# R7FA4C1BD register map
Vendor: Renesas Electronics Corporation; Series: RA4; File version: 1.10.00
CPU: CM33 r0p4, little endian, MPU, FPU, VTOR, 4 interrupt priority bits, 96 interrupts
Registers are 32-bit, read-write, reset 0x0 unless marked. A register's access mark holds for its fields unless they carry their own. Offsets are from the block's base; [hi:lo] are bit positions; {n}, {i} and the like mark numbered series; 'fields as' and 'values as' point back to an identical list.

## PFS — Control Register
Base 0x4001F800
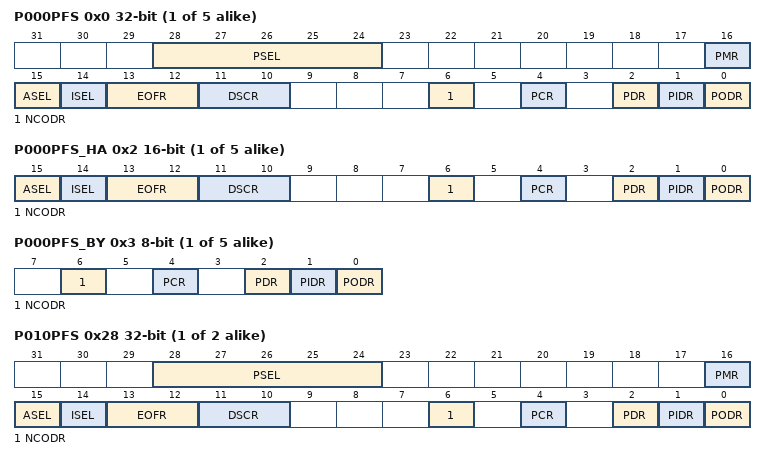
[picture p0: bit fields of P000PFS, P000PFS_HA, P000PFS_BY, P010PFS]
{0x0+4i} P00{i}PFS (i=0..4) (reset mask 0xFFFFFFFD) — Port 00{i} Pin Function Select Register
  [28:24] PSEL — Peripheral Select
  [16] PMR — Port Mode Control
    0=Use as general I/O pin; 1=Use as I/O port for peripheral functions
  [15] ASEL — Analog Input Enable
    0=Do not use as analog pin; 1=Use as analog pin
  [14] ISEL — IRQ Input Enable
    0=Do not use as IRQn input pin; 1=Use as IRQn input pin
  [13:12] EOFR — Event on Falling/Event on Rising
    0=Don't care; 1=Detect rising edge; 2=Detect falling edge; 3=Detect both edges
  [11:10] DSCR — Port Drive Capability
    0=Low drive; 1=Middle drive; 2=Setting prohibited; 3=High drive
  [6] NCODR — N-Channel Open-Drain Control
    0=Output CMOS; 1=Output NMOS open-drain
  [4] PCR — Pull-up Control
    0=Disable input pull-up; 1=Enable input pull-up
  [2] PDR — Port Direction
    0=Input (functions as an input pin); 1=Output (functions as an output pin)
  [1] PIDR ro — Port State
    0=Low level; 1=High level
  [0] PODR — Port Output Data
    0=Output low; 1=Output high
{0x2+4i} P00{i}PFS_HA (i=0..4) 16-bit (reset mask 0xFFFD) (alternate view of P00{i}PFS) — Port 00{i} Pin Function Select Register
  [15] ASEL — Analog Input Enable
    0=Do not use as analog pin; 1=Use as analog pin
  [14] ISEL — IRQ Input Enable
    0=Do not use as IRQn input pin; 1=Use as IRQn input pin
  [13:12] EOFR — Event on Falling/Event on Rising
    values as P000PFS.EOFR
  [11:10] DSCR — Port Drive Capability
    values as P000PFS.DSCR
  [6] NCODR — N-Channel Open-Drain Control
    0=Output CMOS; 1=Output NMOS open-drain
  [4] PCR — Pull-up Control
    0=Disable input pull-up; 1=Enable input pull-up
  [2] PDR — Port Direction
    values as P000PFS.PDR
  [1] PIDR ro — Port State
    0=Low level; 1=High level
  [0] PODR — Port Output Data
    0=Output low; 1=Output high
{0x3+4i} P00{i}PFS_BY (i=0..4) 8-bit (reset mask 0xFD) (alternate view of P00{i}PFS) — Port 00{i} Pin Function Select Register
  [6] NCODR — N-Channel Open-Drain Control
    0=Output CMOS; 1=Output NMOS open-drain
  [4] PCR — Pull-up Control
    0=Disable input pull-up; 1=Enable input pull-up
  [2] PDR — Port Direction
    values as P000PFS.PDR
  [1] PIDR ro — Port State
    0=Low level; 1=High level
  [0] PODR — Port Output Data
    0=Output low; 1=Output high
{0x0+4i} P0{i}PFS (i=10..11) (reset mask 0xFFFFFFFD) — Port 0{i} Pin Function Select Register
  fields as P000PFS
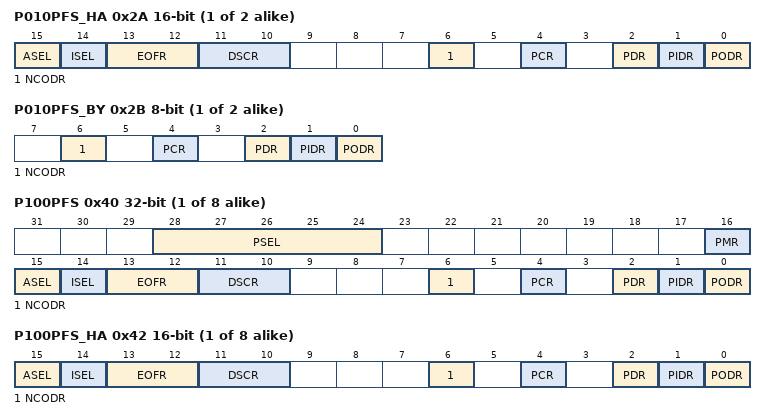
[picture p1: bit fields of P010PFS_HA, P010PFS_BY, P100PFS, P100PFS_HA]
{0x2+4i} P0{i}PFS_HA (i=10..11) 16-bit (reset mask 0xFFFD) (alternate view of P0{i}PFS) — Port 0{i} Pin Function Select Register
  fields as P000PFS_HA
{0x3+4i} P0{i}PFS_BY (i=10..11) 8-bit (reset mask 0xFD) (alternate view of P0{i}PFS) — Port 0{i} Pin Function Select Register
  fields as P000PFS_BY
{0x40+4i} P10{i}PFS (i=0..7) (reset mask 0xFFFFFFFD) — Port 10{i} Pin Function Select Register
  fields as P000PFS
{0x42+4i} P10{i}PFS_HA (i=0..7) 16-bit (reset mask 0xFFFD) (alternate view of P10{i}PFS) — Port 10{i} Pin Function Select Register
  fields as P000PFS_HA
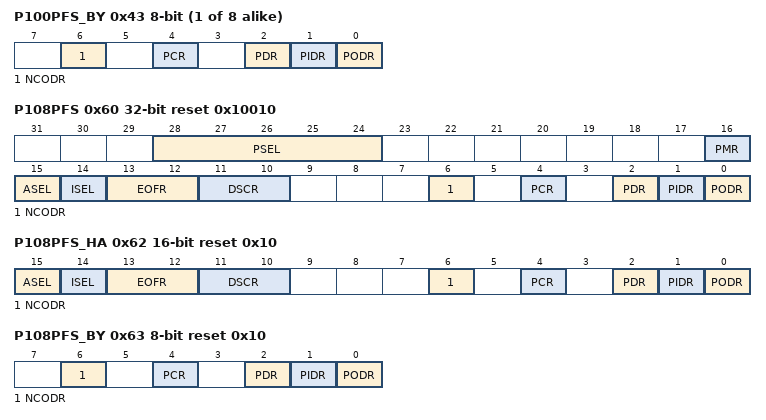
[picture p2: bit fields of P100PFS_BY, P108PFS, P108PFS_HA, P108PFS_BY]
{0x43+4i} P10{i}PFS_BY (i=0..7) 8-bit (reset mask 0xFD) (alternate view of P10{i}PFS) — Port 10{i} Pin Function Select Register
  fields as P000PFS_BY
0x60 P108PFS reset 0x10010 — Port 108 Pin Function Select Register
  fields as P000PFS
0x62 P108PFS_HA 16-bit reset 0x10 (alternate view of P108PFS) — Port 108 Pin Function Select Register
  fields as P000PFS_HA
0x63 P108PFS_BY 8-bit reset 0x10 (alternate view of P108PFS) — Port 108 Pin Function Select Register
  fields as P000PFS_BY
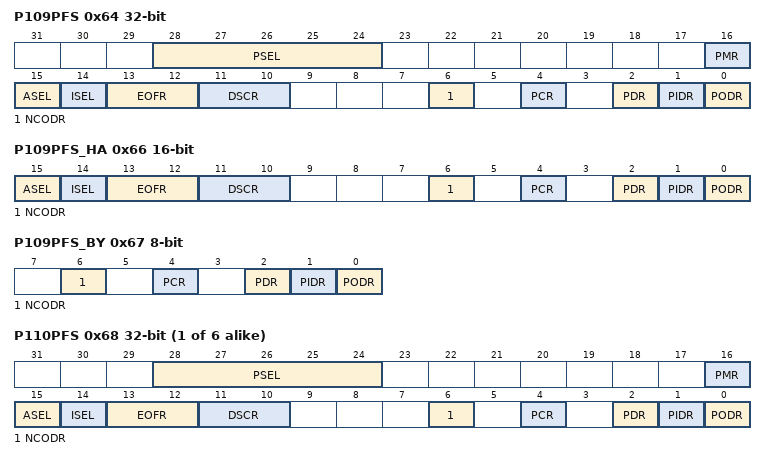
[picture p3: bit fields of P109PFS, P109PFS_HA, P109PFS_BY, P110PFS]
0x64 P109PFS (reset mask 0xFFFFFFFD) — Port 109 Pin Function Select Register
  fields as P000PFS
0x66 P109PFS_HA 16-bit (reset mask 0xFFFD) (alternate view of P109PFS) — Port 109 Pin Function Select Register
  fields as P000PFS_HA
0x67 P109PFS_BY 8-bit (reset mask 0xFD) (alternate view of P109PFS) — Port 109 Pin Function Select Register
  fields as P000PFS_BY
{0x40+4i} P1{i}PFS (i=10..15) (reset mask 0xFFFFFFFD) — Port 1{i} Pin Function Select Register
  fields as P000PFS
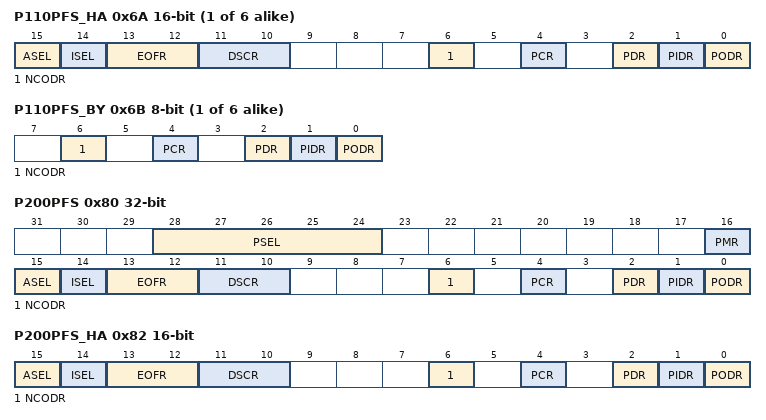
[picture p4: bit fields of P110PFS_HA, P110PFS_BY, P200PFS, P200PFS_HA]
{0x42+4i} P1{i}PFS_HA (i=10..15) 16-bit (reset mask 0xFFFD) (alternate view of P1{i}PFS) — Port 1{i} Pin Function Select Register
  fields as P000PFS_HA
{0x43+4i} P1{i}PFS_BY (i=10..15) 8-bit (reset mask 0xFD) (alternate view of P1{i}PFS) — Port 1{i} Pin Function Select Register
  fields as P000PFS_BY
0x80 P200PFS (reset mask 0xFFFFFFFD) — Port 200 Pin Function Select Register
  fields as P000PFS
0x82 P200PFS_HA 16-bit (reset mask 0xFFFD) (alternate view of P200PFS) — Port 200 Pin Function Select Register
  fields as P000PFS_HA
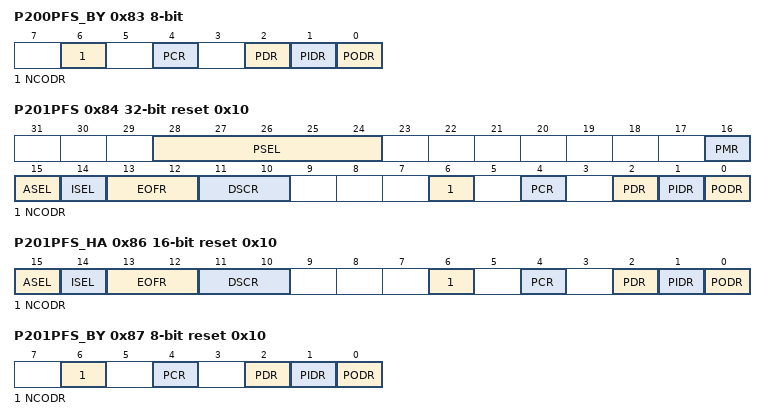
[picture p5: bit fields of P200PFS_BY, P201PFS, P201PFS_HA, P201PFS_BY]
0x83 P200PFS_BY 8-bit (reset mask 0xFD) (alternate view of P200PFS) — Port 200 Pin Function Select Register
  fields as P000PFS_BY
0x84 P201PFS reset 0x10 (reset mask 0xFFFFFFFD) — Port 201 Pin Function Select Register
  fields as P000PFS
0x86 P201PFS_HA 16-bit reset 0x10 (reset mask 0xFFFD) (alternate view of P201PFS) — Port 201 Pin Function Select Register
  fields as P000PFS_HA
0x87 P201PFS_BY 8-bit reset 0x10 (reset mask 0xFD) (alternate view of P201PFS) — Port 201 Pin Function Select Register
  fields as P000PFS_BY
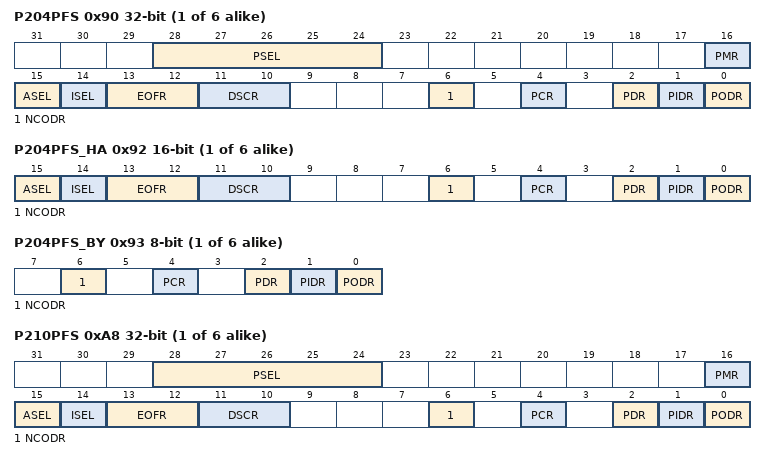
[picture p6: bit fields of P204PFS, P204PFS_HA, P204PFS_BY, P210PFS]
{0x80+4i} P20{i}PFS (i=4..9) (reset mask 0xFFFFFFFD) — Port 20{i} Pin Function Select Register
  fields as P000PFS
{0x82+4i} P20{i}PFS_HA (i=4..9) 16-bit (reset mask 0xFFFD) (alternate view of P20{i}PFS) — Port 20{i} Pin Function Select Register
  fields as P000PFS_HA
{0x83+4i} P20{i}PFS_BY (i=4..9) 8-bit (reset mask 0xFD) (alternate view of P20{i}PFS) — Port 20{i} Pin Function Select Register
  fields as P000PFS_BY
{0x80+4i} P2{i}PFS (i=10..15) (reset mask 0xFFFFFFFD) — Port 2{i} Pin Function Select Register
  fields as P000PFS
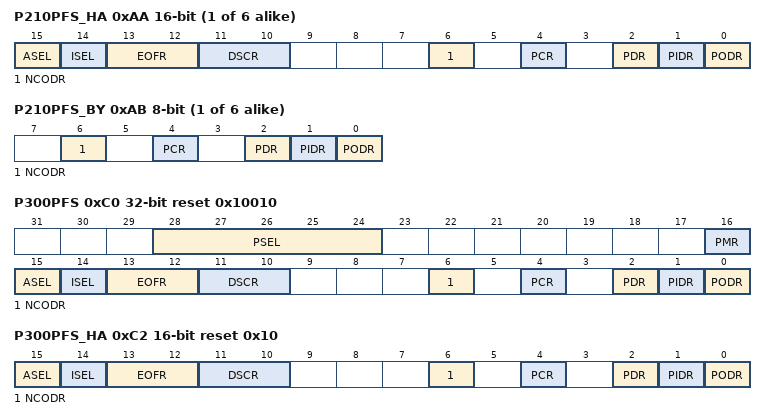
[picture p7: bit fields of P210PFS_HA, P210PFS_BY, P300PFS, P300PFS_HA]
{0x82+4i} P2{i}PFS_HA (i=10..15) 16-bit (reset mask 0xFFFD) (alternate view of P2{i}PFS) — Port 2{i} Pin Function Select Register
  fields as P000PFS_HA
{0x83+4i} P2{i}PFS_BY (i=10..15) 8-bit (reset mask 0xFD) (alternate view of P2{i}PFS) — Port 2{i} Pin Function Select Register
  fields as P000PFS_BY
0xC0 P300PFS reset 0x10010 (reset mask 0xFFFFFFFD) — Port 300 Pin Function Select Register
  fields as P000PFS
0xC2 P300PFS_HA 16-bit reset 0x10 (reset mask 0xFFFD) (alternate view of P300PFS) — Port 300 Pin Function Select Register
  fields as P000PFS_HA
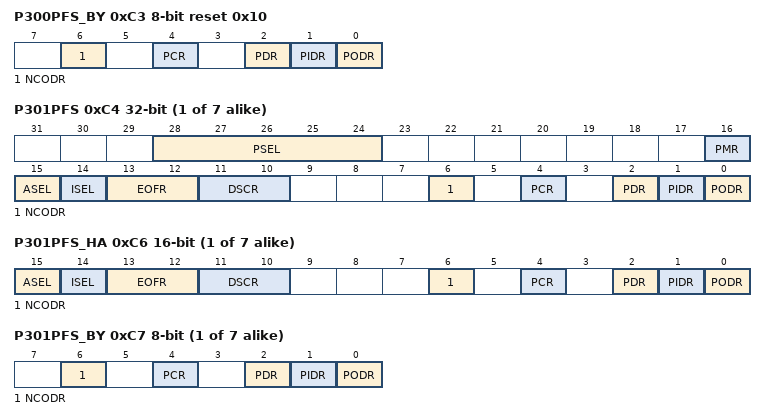
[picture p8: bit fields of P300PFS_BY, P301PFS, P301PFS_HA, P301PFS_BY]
0xC3 P300PFS_BY 8-bit reset 0x10 (reset mask 0xFD) (alternate view of P300PFS) — Port 300 Pin Function Select Register
  fields as P000PFS_BY
{0xC0+4i} P30{i}PFS (i=1..7) (reset mask 0xFFFFFFFD) — Port 30{i} Pin Function Select Register
  fields as P000PFS
{0xC2+4i} P30{i}PFS_HA (i=1..7) 16-bit (reset mask 0xFFFD) (alternate view of P30{i}PFS) — Port 30{i} Pin Function Select Register
  fields as P000PFS_HA
{0xC3+4i} P30{i}PFS_BY (i=1..7) 8-bit (reset mask 0xFD) (alternate view of P30{i}PFS) — Port 30{i} Pin Function Select Register
  fields as P000PFS_BY
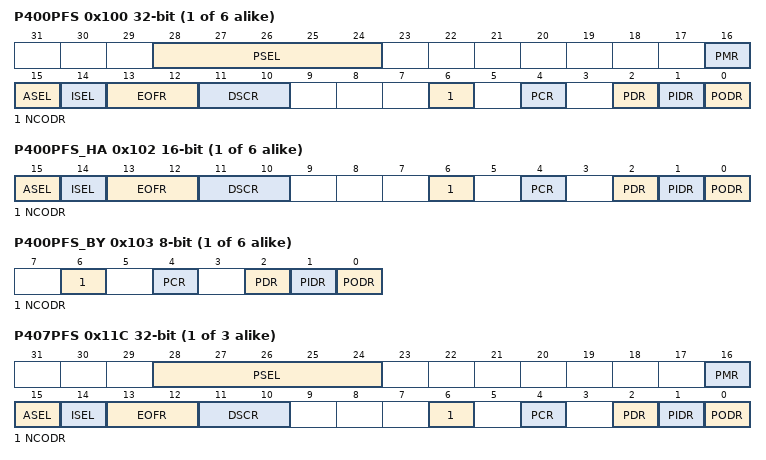
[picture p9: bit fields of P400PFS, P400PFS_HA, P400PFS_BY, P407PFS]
{0x100+4i} P40{i}PFS (i=0..5) (reset mask 0xFFFFFFFD) — Port 40{i} Pin Function Select Register
  fields as P000PFS
{0x102+4i} P40{i}PFS_HA (i=0..5) 16-bit (reset mask 0xFFFD) (alternate view of P40{i}PFS) — Port 40{i} Pin Function Select Register
  fields as P000PFS_HA
{0x103+4i} P40{i}PFS_BY (i=0..5) 8-bit (reset mask 0xFD) (alternate view of P40{i}PFS) — Port 40{i} Pin Function Select Register
  fields as P000PFS_BY
{0x100+4i} P40{i}PFS (i=7..9) (reset mask 0xFFFFFFFD) — Port 40{i} Pin Function Select Register
  fields as P000PFS
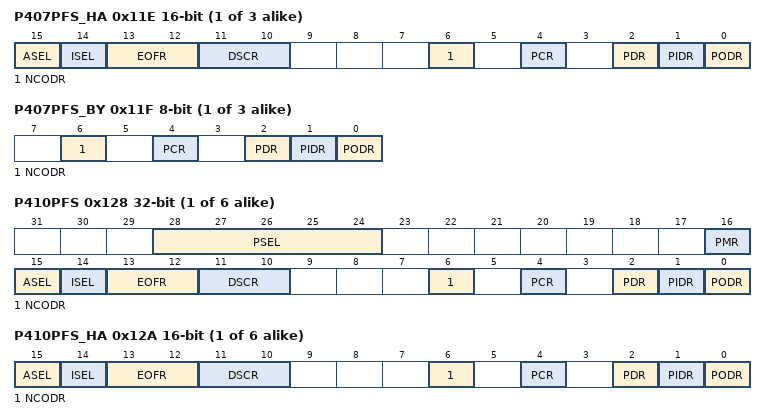
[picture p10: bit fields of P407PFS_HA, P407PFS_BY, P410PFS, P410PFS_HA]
{0x102+4i} P40{i}PFS_HA (i=7..9) 16-bit (reset mask 0xFFFD) (alternate view of P40{i}PFS) — Port 40{i} Pin Function Select Register
  fields as P000PFS_HA
{0x103+4i} P40{i}PFS_BY (i=7..9) 8-bit (reset mask 0xFD) (alternate view of P40{i}PFS) — Port 40{i} Pin Function Select Register
  fields as P000PFS_BY
{0x100+4i} P4{i}PFS (i=10..15) (reset mask 0xFFFFFFFD) — Port 4{i} Pin Function Select Register
  fields as P000PFS
{0x102+4i} P4{i}PFS_HA (i=10..15) 16-bit (reset mask 0xFFFD) (alternate view of P4{i}PFS) — Port 4{i} Pin Function Select Register
  fields as P000PFS_HA
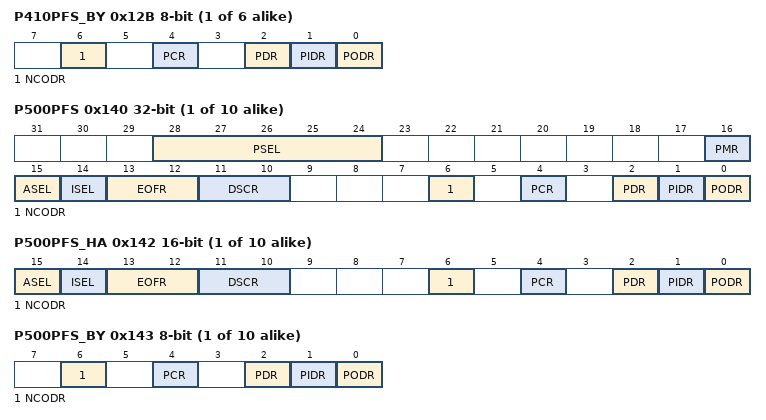
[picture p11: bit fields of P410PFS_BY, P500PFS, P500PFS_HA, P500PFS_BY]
{0x103+4i} P4{i}PFS_BY (i=10..15) 8-bit (reset mask 0xFD) (alternate view of P4{i}PFS) — Port 4{i} Pin Function Select Register
  fields as P000PFS_BY
{0x140+4i} P50{i}PFS (i=0..9) (reset mask 0xFFFFFFFD) — Port 50{i} Pin Function Select Register
  fields as P000PFS
{0x142+4i} P50{i}PFS_HA (i=0..9) 16-bit (reset mask 0xFFFD) (alternate view of P50{i}PFS) — Port 50{i} Pin Function Select Register
  fields as P000PFS_HA
{0x143+4i} P50{i}PFS_BY (i=0..9) 8-bit (reset mask 0xFD) (alternate view of P50{i}PFS) — Port 50{i} Pin Function Select Register
  fields as P000PFS_BY
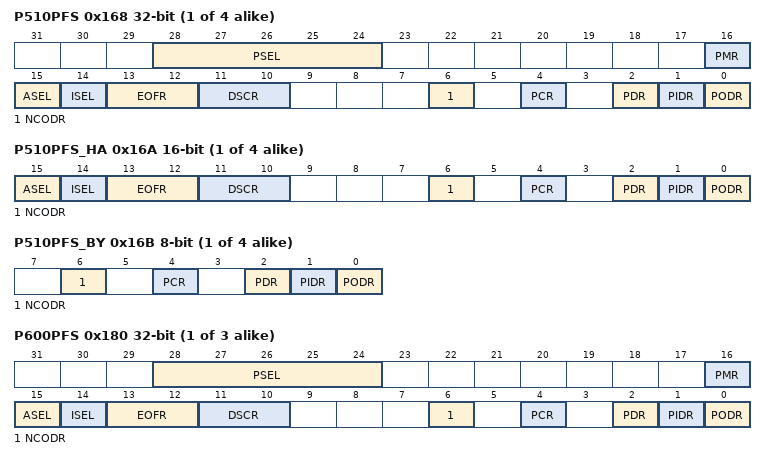
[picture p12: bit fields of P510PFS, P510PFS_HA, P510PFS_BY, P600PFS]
{0x140+4i} P5{i}PFS (i=10..13) (reset mask 0xFFFFFFFD) — Port 5{i} Pin Function Select Register
  fields as P000PFS
{0x142+4i} P5{i}PFS_HA (i=10..13) 16-bit (reset mask 0xFFFD) (alternate view of P5{i}PFS) — Port 5{i} Pin Function Select Register
  fields as P000PFS_HA
{0x143+4i} P5{i}PFS_BY (i=10..13) 8-bit (reset mask 0xFD) (alternate view of P5{i}PFS) — Port 5{i} Pin Function Select Register
  fields as P000PFS_BY
{0x180+4i} P60{i}PFS (i=0..2) (reset mask 0xFFFFFFFD) — Port 60{i} Pin Function Select Register
  fields as P000PFS
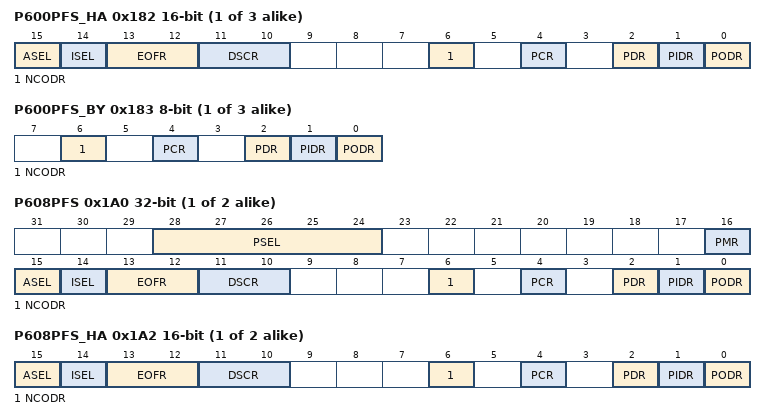
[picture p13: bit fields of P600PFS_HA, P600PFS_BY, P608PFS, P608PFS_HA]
{0x182+4i} P60{i}PFS_HA (i=0..2) 16-bit (reset mask 0xFFFD) (alternate view of P60{i}PFS) — Port 60{i} Pin Function Select Register
  fields as P000PFS_HA
{0x183+4i} P60{i}PFS_BY (i=0..2) 8-bit (reset mask 0xFD) (alternate view of P60{i}PFS) — Port 60{i} Pin Function Select Register
  fields as P000PFS_BY
{0x180+4i} P60{i}PFS (i=8..9) (reset mask 0xFFFFFFFD) — Port 60{i} Pin Function Select Register
  fields as P000PFS
{0x182+4i} P60{i}PFS_HA (i=8..9) 16-bit (reset mask 0xFFFD) (alternate view of P60{i}PFS) — Port 60{i} Pin Function Select Register
  fields as P000PFS_HA
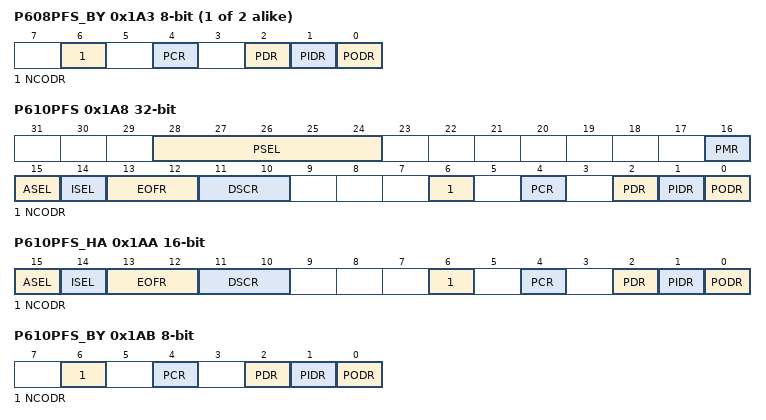
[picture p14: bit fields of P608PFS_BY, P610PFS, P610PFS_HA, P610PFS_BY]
{0x183+4i} P60{i}PFS_BY (i=8..9) 8-bit (reset mask 0xFD) (alternate view of P60{i}PFS) — Port 60{i} Pin Function Select Register
  fields as P000PFS_BY
0x1A8 P610PFS (reset mask 0xFFFFFFFD) — Port 6n Pin Function Select Register
  fields as P000PFS
0x1AA P610PFS_HA 16-bit (reset mask 0xFFFD) (alternate view of P610PFS) — Port 6n Pin Function Select Register
  fields as P000PFS_HA
0x1AB P610PFS_BY 8-bit (reset mask 0xFD) (alternate view of P610PFS) — Port 6n Pin Function Select Register
  fields as P000PFS_BY
0x1E0 P708PFS (reset mask 0xFFFFFFFD) — Port 708 Pin Function Select Register
  fields as P000PFS
0x1E2 P708PFS_HA 16-bit (reset mask 0xFFFD) (alternate view of P708PFS) — Port 708 Pin Function Select Register
  fields as P000PFS_HA
0x1E3 P708PFS_BY 8-bit (reset mask 0xFD) (alternate view of P708PFS) — Port 708 Pin Function Select Register
  fields as P000PFS_BY
{0x1C8+4i} P80{i}PFS (i=14..15) (reset mask 0xFFFFFFFD) — Port 80{i} Pin Function Select Register
  fields as P000PFS
{0x1CA+4i} P80{i}PFS_HA (i=14..15) 16-bit (reset mask 0xFFFD) (alternate view of P80{i}PFS) — Port 80{i} Pin Function Select Register
  fields as P000PFS_HA
{0x1CB+4i} P80{i}PFS_BY (i=14..15) 8-bit (reset mask 0xFD) (alternate view of P80{i}PFS) — Port 80{i} Pin Function Select Register
  fields as P000PFS_BY
0x503 PWPR 8-bit reset 0x80 — Write-Protect Register
  [7] B0WI — PFSWE Bit Write Disable
    0=Writing to the PFSWE bit is enabled; 1=Writing to the PFSWE bit is disabled
  [6] PFSWE — PmnPFS Register Write Enable
    0=Writing to the PmnPFS register is disabled; 1=Writing to the PmnPFS register is enabled
0x505 PWPRS 8-bit reset 0x80 — Write-Protect Register for Secure
  [7] B0WI — PFSWE Bit Write Disable
    0=Enable writes the PFSWE bit; 1=Disable writes to the PFSWE bit
  [6] PFSWE — PmnPFS Register Write Enable
    0=Disable writes to the PmnPFS register; 1=Enable writes to the PmnPFS register
0x50C PRWCNTR 8-bit reset 0x1 — Set Wait Control Register
  [3:0] WAIT — Wait Cycle Control Bit
    0=Setting prohibited; {v}=insert wait cycle {v} (v=1..15)
{0x510+2i} P{i}SAR (i=0..8) 16-bit reset 0xFFFF — Port Security Attribution Register
  [15:0] PMNSA — Pmn Security Attribution
    0=Secure; 1=Non-secure
0x540 PSAR 16-bit reset 0xFFFF — PORT Security Attribution Register
  [0] PORTSA0 — PRWCNTR Security Attribution
    0=Secure; 1=NonSecure

## Notices in the file
This software is supplied by Renesas Electronics Corporation and is only intended for
use with Renesas products. No other uses are authorized. This software is owned by
Renesas Electronics Corporation and is protected under all applicable laws, including
copyright laws.
THIS SOFTWARE IS PROVIDED "AS IS" AND RENESAS MAKES NO WARRANTIES REGARDING
THIS SOFTWARE, WHETHER EXPRESS, IMPLIED OR STATUTORY, INCLUDING BUT NOT LIMITED TO
WARRANTIES OF MERCHANTABILITY, FITNESS FOR A PARTICULAR PURPOSE AND NON-INFRINGEMENT.
ALL SUCH WARRANTIES ARE EXPRESSLY DISCLAIMED. TO THE MAXIMUM EXTENT PERMITTED NOT
PROHIBITED BY LAW, NEITHER RENESAS ELECTRONICS CORPORATION NOR ANY OF ITS AFFILIATED
COMPANIES SHALL BE LIABLE FOR ANY DIRECT, INDIRECT, SPECIAL, INCIDENTAL OR CONSEQUENTIAL
DAMAGES FOR ANY REASON RELATED TO THIS SOFTWARE, EVEN IF RENESAS OR ITS AFFILIATES HAVE
BEEN ADVISED OF THE POSSIBILITY OF SUCH DAMAGES.
Renesas reserves the right, without notice, to make changes to this software and to
discontinue the availability of this software. By using this software, you agree to
the additional terms and conditions found by accessing the following link:
http://www.renesas.com/disclaimer
